# RockChip_RK3588 register map
Vendor: RockChip Electronics Co., Ltd.; Series: RK3588; File version: 0.1
Registers are 32-bit, read-write, no defined reset value unless marked. A register's access mark holds for its fields unless they carry their own. Offsets are from the block's base; [hi:lo] are bit positions; {n}, {i} and the like mark numbered series; 'fields as' and 'values as' point back to an identical list.

## GRF_LITCORE
Base 0xFD594000
0x20 MEM_CFG_HSSPRF_L — Memory Configuration Register For HSSPRF
  [15:0] GRF_LITCORE_MEM_CFG_HSSPRF_L — bit 0: TEST1 bit 1: TEST_RNM bit 4~2: RM bit 5: WMD bit 7: LS bit 13~12: RA
0x28 MEM_CFG_HSDPRF_L — Memory Configuration Register For HSDPRF Low
  [15:0] GRF_LITCORE_MEM_CFG_HSDPRF_L — bit 0: TEST1A bit 1: TEST_RNMA bit 5~2: RMA bit 6: WMDA bit 8: LS bit 14~13: RA
0x2C MEM_CFG_HSDPRF_H — Memory Configuration Register For HSDPRF Low
  [15:0] GRF_LITCORE_MEM_CFG_HSDPRF_H — bit 1: TEST1B bit 5~2: RMB
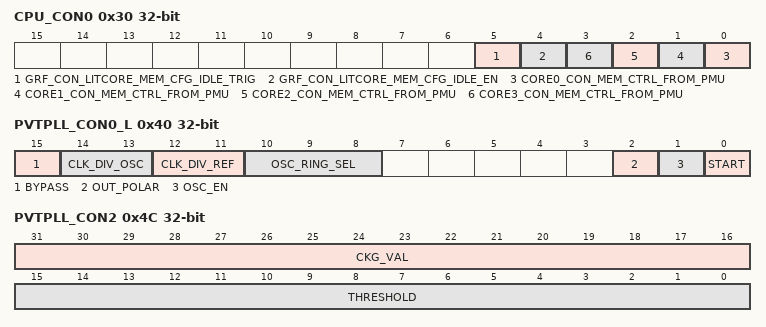
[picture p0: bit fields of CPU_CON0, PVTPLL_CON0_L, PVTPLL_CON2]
0x30 CPU_CON0 — CPU Control Register 0
  [5] GRF_CON_LITCORE_MEM_CFG_IDLE_TRIG — A 0 to 1 trigger of grf_con_litcore_mem_cfg_idle_trig will cause a mem_cfg change when grf_con_litcore_mem_cfg_idle_en equals to 1.
  [4] GRF_CON_LITCORE_MEM_CFG_IDLE_EN
    0=SW_IMMEDIATELY (Mem_cfg is changed by software immediately); 1=ALL_WFI (Mem_cfg is changed when all cpu in wfi)
  [n] CORE{n}_CON_MEM_CTRL_FROM_PMU (n=0..3)
    0=GRF (Mem_cfg is driven by grf); 1=PMU (Mem_cfg is driven by pmu)
0x40 PVTPLL_CON0_L — PVTPLL Control Register 0 Low
  [15] BYPASS
    0=SUPPORT (Support glitch-free frequency conversion.); 1=NOT_SUPPORT
  [14:13] CLK_DIV_OSC — Frequency division factor for osc_clk.
  [12:11] CLK_DIV_REF — Frequency division factor for ref_clk.
  [10:8] OSC_RING_SEL — Oscillator ring channel select.
  [2] OUT_POLAR
    0=OUT_1 (Out=1 when need to increase volt.); 1=OUT_0 (Out=0 when need to increase volt.)
  [1] OSC_EN — Oscillator ring enable.
    0=DISABLE; 1=ENABLE
  [0] START
    1=START (PVTPLL monitor start.)
0x44 PVTPLL_CON0_H — PVTPLL Control Register 0 High
  [5:0] RING_LENGTH_SEL — Oscillator ring inverter length select.
0x48 PVTPLL_CON1 — PVTPLL Control Register 1
  [31:0] CAL_CNT — Target frequency value.
0x4C PVTPLL_CON2 — PVTPLL Control Register 2
  [31:16] CKG_VAL — Clock gating interval control count value.
  [15:0] THRESHOLD — Count difference threshold value.
0x50 PVTPLL_CON3 — PVTPLL Control Register 3
  [31:0] REF_CNT — Frequency measurement period setting value.

## GRF_PMU0
Base 0xFD588000
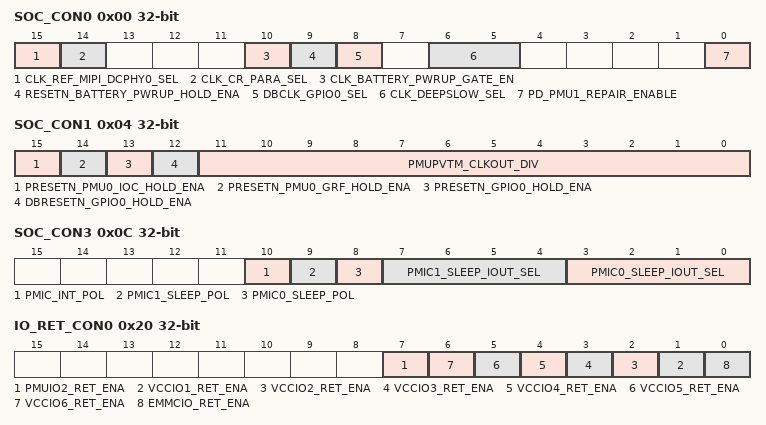
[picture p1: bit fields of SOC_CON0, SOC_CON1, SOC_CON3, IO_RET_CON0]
0x00 SOC_CON0 — System control register 0
  [15] CLK_REF_MIPI_DCPHY0_SEL — Clock source selection for clk_ref_mipi_dcphy0.
    0=GENERATED_CLOCK (Select from generated clock); 1=OSCILLATOR (Select from oscillator)
  [14] CLK_CR_PARA_SEL — Clock source selection for clk_cr_para.
    0=INV_OSCILLATOR (Select from inverter of oscillator); 1=GENERATED_CLOCK (Select from generated clock)
  [10] CLK_BATTERY_PWRUP_GATE_EN — Enable clock gating for battery power up logic.
    0=DISABLE; 1=ENABLE
  [9] RESETN_BATTERY_PWRUP_HOLD_ENA — Enable reset hold for battery power up logic.
    0=DISABLE; 1=ENABLE
  [8] DBCLK_GPIO0_SEL — Clock source selection for dbclk_gpio0.
    0=OSCILLATOR (Select from oscillator); 1=CLK_DEEPSLOW (Select from clk_deepslow)
  [6:5] CLK_DEEPSLOW_SEL — Clock source selection for clk_deepslow. Others: Reserved.
    0=OSC_OUT (Select from divider output of oscillator); 1=EXT_IO_CLK (Select from external IO clock); 2=PMU_PVTM_OUT (Select from divider output of PMU_PVTM)
  [0] PD_PMU1_REPAIR_ENABLE — Enable memory repair for PD_PMU1.
    0=DISABLE; 1=ENABLE
0x04 SOC_CON1 — System control register 1
  [15] PRESETN_PMU0_IOC_HOLD_ENA — Enable reset hold for presetn_pmu0_ioc.
    0=DISABLE; 1=ENABLE
  [14] PRESETN_PMU0_GRF_HOLD_ENA — Enable reset hold for presetn_pmu0_grf.
    0=DISABLE; 1=ENABLE
  [13] PRESETN_GPIO0_HOLD_ENA — Enable reset hold for presetn_gpio0.
    0=DISABLE; 1=ENABLE
  [12] DBRESETN_GPIO0_HOLD_ENA — Enable reset hold for dbresetn_gpio0.
    0=DISABLE; 1=ENABLE
  [11:0] PMUPVTM_CLKOUT_DIV — Clock divide factor for clock generated by PMU_PVTM
0x08 SOC_CON2 — System control register 2
  [13:0] PMU0_MEM_CFG_HDSPRF — Interface configuration for HDSPRF type memory in PD_PMU0. Bit[0]: TEST1 Bit[1]: TEST_RNM Bit[4:2]: RM Bit[5]: WMD Bit[7]: LS Bit[11:10]: WPULSE Bit[13:12]: RA Other bits: Reserved
0x0C SOC_CON3 — System control register 3
  [10] PMIC_INT_POL — Polarity of PMIC int.
    0=ACTIVE_HIGH; 1=ACTIVE_LOW
  [9] PMIC1_SLEEP_POL — Polarity of pmic1_sleep.
    0=ACTIVE_HIGH; 1=ACTIVE_LOW
  [8] PMIC0_SLEEP_POL — Polarity of pmic0_sleep.
    0=ACTIVE_HIGH; 1=ACTIVE_LOW
  [7:4] PMIC1_SLEEP_IOUT_SEL — Source selection for pmic1_sleep.
    1=VD_NPU (VD_NPU power off request); 2=VD_GPU (VD_GPU power off request); 3=VD_BIGCORE0 (VD_BIGCORE0 power off request); 4=VD_BIGCORE1 (VD_BIGCORE1 power off request); 5=VD_DSU (VD_DSU power off request); 6=VD_VCODEC (VD_VCODEC power off request); 7=VD_DDR (VD_DDR power off request); 8=LOW_DEEP_LOW_POWER (Low power mode or deep low power mode); 9=CHIP_RESET (Chip reset output); 10=DEEP_LOW_POWER (Deep low power mode); 11=LOW_POWER (Low power mode)
  [3:0] PMIC0_SLEEP_IOUT_SEL — Source selection for pmic0_sleep.
    values as PMIC1_SLEEP_IOUT_SEL
0x20 IO_RET_CON0 — IO retention control register 0
  [all] fields
    0=DISABLE; 1=ENABLE
  [7] PMUIO2_RET_ENA — Enable PMUIO2 retention mode by hardware.
  [n] VCCIO{n}_RET_ENA (n=1..6) — Enable VCCIO{n} retention mode by hardware.
  [0] EMMCIO_RET_ENA — Enable EMMCIO retention mode by hardware.
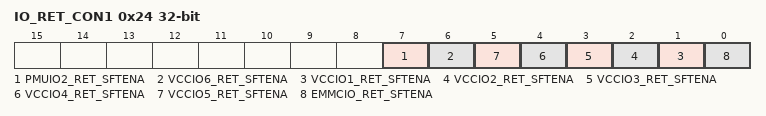
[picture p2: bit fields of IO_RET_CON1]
0x24 IO_RET_CON1 — IO retention control register 1
  [all] fields
    0=DISABLE; 1=ENABLE
  [7] PMUIO2_RET_SFTENA — Enable PMUIO2 retention mode by software.
  [6] VCCIO6_RET_SFTENA — Enable VCCIO1 retention mode by software.
  [n] VCCIO{n}_RET_SFTENA (n=1..5) — Enable VCCIO{n} retention mode by software.
  [0] EMMCIO_RET_SFTENA — Enable EMMCIO retention mode by software.
{0x60+4i} OS_REG{i} (i=8..11) — Operation system register {i}
